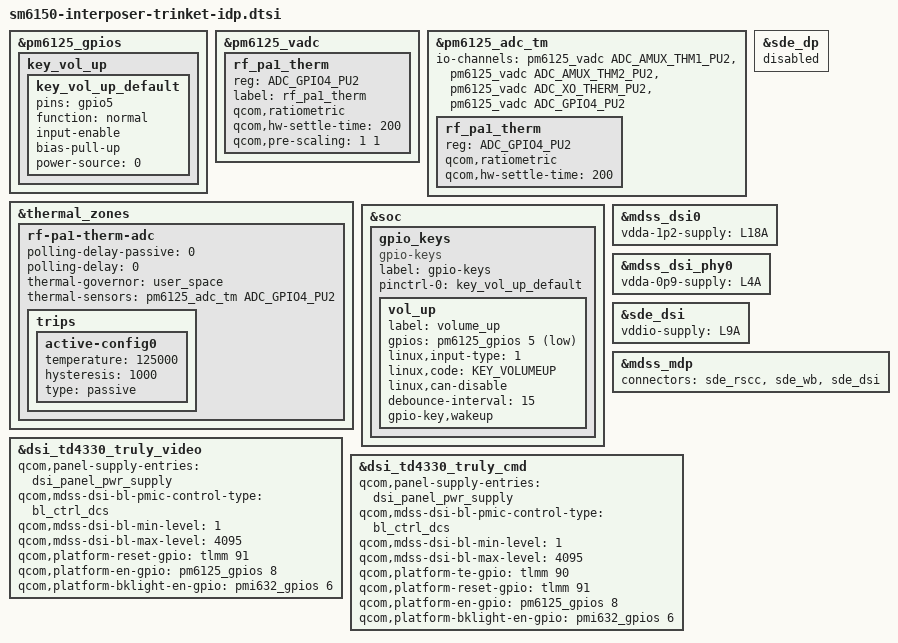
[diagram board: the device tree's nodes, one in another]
/*
 * Copyright (c) 2018-2019, The Linux Foundation. All rights reserved.
 *
 * This program is free software; you can redistribute it and/or modify
 * it under the terms of the GNU General Public License version 2 and
 * only version 2 as published by the Free Software Foundation.
 *
 * This program is distributed in the hope that it will be useful,
 * but WITHOUT ANY WARRANTY; without even the implied warranty of
 * MERCHANTABILITY or FITNESS FOR A PARTICULAR PURPOSE.  See the
 * GNU General Public License for more details.
 */

#include <dt-bindings/gpio/gpio.h>
#include <dt-bindings/input/input.h>
#include "sm6150-sde-display.dtsi"
#include <dt-bindings/iio/qcom,spmi-vadc.h>

&pm6125_gpios {
	key_vol_up {
		key_vol_up_default: key_vol_up_default {
			pins = "gpio5";
			function = "normal";
			input-enable;
			bias-pull-up;
			power-source = <0>;
		};
	};
};

&pm6125_vadc {
	rf_pa1_therm {
		reg = <ADC_GPIO4_PU2>;
		label = "rf_pa1_therm";
		qcom,ratiometric;
		qcom,hw-settle-time = <200>;
		qcom,pre-scaling = <1 1>;
	};
};

&pm6125_adc_tm {
	io-channels = <&pm6125_vadc ADC_AMUX_THM1_PU2>,
			<&pm6125_vadc ADC_AMUX_THM2_PU2>,
			<&pm6125_vadc ADC_XO_THERM_PU2>,
			<&pm6125_vadc ADC_GPIO4_PU2>;

	rf_pa1_therm {
		reg = <ADC_GPIO4_PU2>;
		qcom,ratiometric;
		qcom,hw-settle-time = <200>;
	};
};

&thermal_zones {
	rf-pa1-therm-adc {
		polling-delay-passive = <0>;
		polling-delay = <0>;
		thermal-governor = "user_space";
		thermal-sensors = <&pm6125_adc_tm ADC_GPIO4_PU2>;
		trips {
			active-config0 {
				temperature = <125000>;
				hysteresis = <1000>;
				type = "passive";
			};
		};
	};
};

&soc {
	gpio_keys {
		compatible = "gpio-keys";
		label = "gpio-keys";

		pinctrl-names = "default";
		pinctrl-0 = <&key_vol_up_default>;

		vol_up {
			label = "volume_up";
			gpios = <&pm6125_gpios 5 GPIO_ACTIVE_LOW>;
			linux,input-type = <1>;
			linux,code = <KEY_VOLUMEUP>;
			linux,can-disable;
			debounce-interval = <15>;
			gpio-key,wakeup;
		};
	};
};

&sde_dp {
	/delete-property/ qcom,dp-usbpd-detection;
	status = "disabled";
};

&mdss_dsi0 {
	vdda-1p2-supply = <&L18A>;
};

&mdss_dsi_phy0 {
	vdda-0p9-supply = <&L4A>;
};

&sde_dsi {
	vddio-supply = <&L9A>;
};

&mdss_mdp {
	connectors = <&sde_rscc &sde_wb &sde_dsi>;
};

&dsi_td4330_truly_video {
	qcom,panel-supply-entries = <&dsi_panel_pwr_supply>;
	qcom,mdss-dsi-bl-pmic-control-type = "bl_ctrl_dcs";
	qcom,mdss-dsi-bl-min-level = <1>;
	qcom,mdss-dsi-bl-max-level = <4095>;
	qcom,platform-reset-gpio = <&tlmm 91 0>;
	qcom,platform-en-gpio = <&pm6125_gpios 8 0>;
	qcom,platform-bklight-en-gpio = <&pmi632_gpios 6 0>;
};

&dsi_td4330_truly_cmd {
	qcom,panel-supply-entries = <&dsi_panel_pwr_supply>;
	qcom,mdss-dsi-bl-pmic-control-type = "bl_ctrl_dcs";
	qcom,mdss-dsi-bl-min-level = <1>;
	qcom,mdss-dsi-bl-max-level = <4095>;
	qcom,platform-te-gpio = <&tlmm 90 0>;
	qcom,platform-reset-gpio = <&tlmm 91 0>;
	qcom,platform-en-gpio = <&pm6125_gpios 8 0>;
	qcom,platform-bklight-en-gpio = <&pmi632_gpios 6 0>;
};
